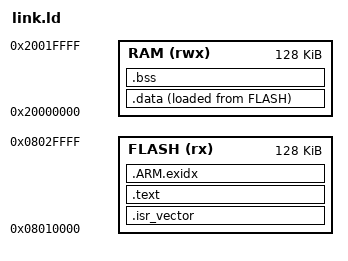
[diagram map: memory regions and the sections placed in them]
/* PRO-800 application: the fixed bootloader lives at 0x08000000 and jumps to the vector table at
   0x08010000. The packer accepts at most 128 kB: flash sector 4 (64 kB) and the first half of sector 5, which the
   bootloader erases and programs with every update (tested 0.8.4, all code from 0x08020000). */

ENTRY(Reset_Handler)

MEMORY
{
    FLASH (rx)  : ORIGIN = 0x08010000, LENGTH = 128K /* sector 4 and half of sector 5 */
    RAM   (rwx) : ORIGIN = 0x20000000, LENGTH = 128K
}

_estack = ORIGIN(RAM) + LENGTH(RAM);

SECTIONS
{
    .isr_vector : { KEEP(*(.isr_vector)) } > FLASH

    .text :
    {
        *(.text*)
        *(.rodata*)
        . = ALIGN(4);
    } > FLASH

    .ARM.exidx : { *(.ARM.exidx*) } > FLASH

    _sidata = LOADADDR(.data);

    .data :
    {
        _sdata = .;
        *(.ramfunc*)
        *(.data*)
        . = ALIGN(4);
        _edata = .;
    } > RAM AT > FLASH

    .bss (NOLOAD) :
    {
        _sbss = .;
        *(.bss*)
        *(COMMON)
        . = ALIGN(4);
        _ebss = .;
    } > RAM
}
